AUTOSAR XML (schema 3.1.2)
package /Components/SWC_VSReg
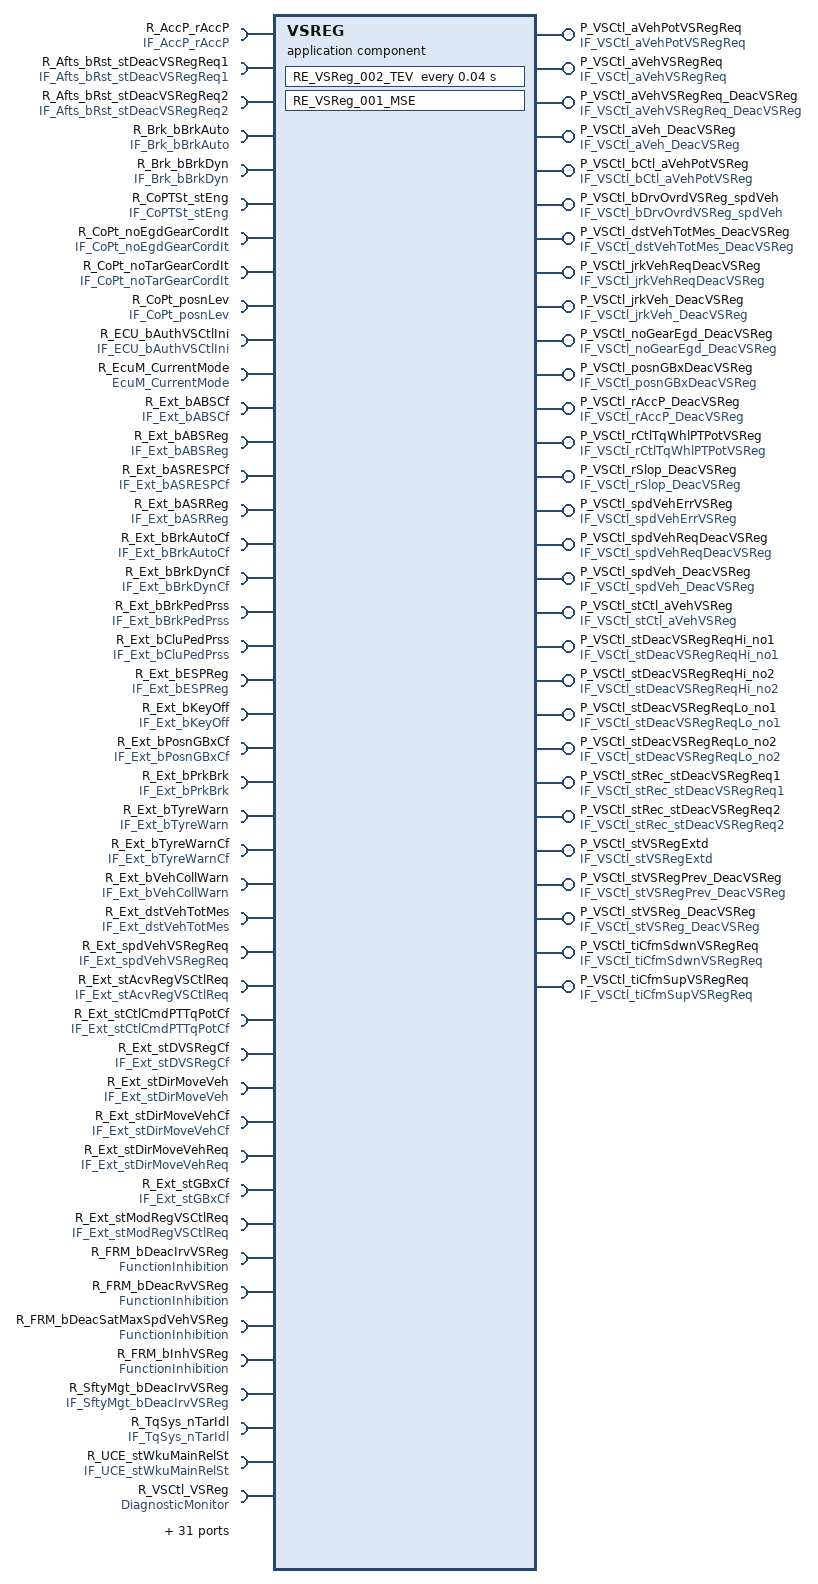
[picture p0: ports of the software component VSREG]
  application software component type VSREG  # VSReg
    29 x provide port:
      P_VSCtl_aVehPotVSRegReq: unqueued-sender-com-spec{data-element=VSCtl_aVehPotVSRegReq, can-invalidate=false, init-value=ConstantValue}, provided-interface=IF_VSCtl_aVehPotVSRegReq
      P_VSCtl_aVehVSRegReq: unqueued-sender-com-spec{data-element=VSCtl_aVehVSRegReq, can-invalidate=false, init-value=ConstantValue1}, provided-interface=IF_VSCtl_aVehVSRegReq
      P_VSCtl_aVehVSRegReq_DeacVSReg: unqueued-sender-com-spec{data-element=VSCtl_aVehVSRegReq_DeacVSReg, can-invalidate=false, init-value=C_SInt16_m10240}, provided-interface=IF_VSCtl_aVehVSRegReq_DeacVSReg
      P_VSCtl_aVeh_DeacVSReg: unqueued-sender-com-spec{data-element=VSCtl_aVeh_DeacVSReg, can-invalidate=false, init-value=C_SInt16_0}, provided-interface=IF_VSCtl_aVeh_DeacVSReg
      P_VSCtl_bCtl_aVehPotVSReg: unqueued-sender-com-spec{data-element=VSCtl_bCtl_aVehPotVSReg, can-invalidate=false, init-value=ConstantValue3}, provided-interface=IF_VSCtl_bCtl_aVehPotVSReg
      P_VSCtl_bDrvOvrdVSReg_spdVeh: unqueued-sender-com-spec{data-element=VSCtl_bDrvOvrdVSReg_spdVeh, can-invalidate=false, init-value=ConstantValue5}, provided-interface=IF_VSCtl_bDrvOvrdVSReg_spdVeh
      P_VSCtl_dstVehTotMes_DeacVSReg: unqueued-sender-com-spec{data-element=VSCtl_dstVehTotMes_DeacVSReg, can-invalidate=false, init-value=C_UInt32_0}, provided-interface=IF_VSCtl_dstVehTotMes_DeacVSReg
      P_VSCtl_jrkVehReqDeacVSReg: unqueued-sender-com-spec{data-element=VSCtl_jrkVehReqDeacVSReg, can-invalidate=false, init-value=C_SInt16_07}, provided-interface=IF_VSCtl_jrkVehReqDeacVSReg
      P_VSCtl_jrkVeh_DeacVSReg: unqueued-sender-com-spec{data-element=VSCtl_jrkVeh_DeacVSReg, can-invalidate=false, init-value=C_SInt16_09}, provided-interface=IF_VSCtl_jrkVeh_DeacVSReg
      P_VSCtl_noGearEgd_DeacVSReg: unqueued-sender-com-spec{data-element=VSCtl_noGearEgd_DeacVSReg, can-invalidate=false, init-value=C_SInt8_0}, provided-interface=IF_VSCtl_noGearEgd_DeacVSReg
      P_VSCtl_posnGBxDeacVSReg: unqueued-sender-com-spec{data-element=VSCtl_posnGBxDeacVSReg, can-invalidate=false, init-value=C_UInt8_0}, provided-interface=IF_VSCtl_posnGBxDeacVSReg
      P_VSCtl_rAccP_DeacVSReg: unqueued-sender-com-spec{data-element=VSCtl_rAccP_DeacVSReg, can-invalidate=false, init-value=C_UInt16_12800}, provided-interface=IF_VSCtl_rAccP_DeacVSReg
      P_VSCtl_rCtlTqWhlPTPotVSReg: unqueued-sender-com-spec{data-element=VSCtl_rCtlTqWhlPTPotVSReg, can-invalidate=false, init-value=ConstantValue11}, provided-interface=IF_VSCtl_rCtlTqWhlPTPotVSReg
      P_VSCtl_rSlop_DeacVSReg: unqueued-sender-com-spec{data-element=VSCtl_rSlop_DeacVSReg, can-invalidate=false, init-value=C_SInt16_013}, provided-interface=IF_VSCtl_rSlop_DeacVSReg
      P_VSCtl_spdVehErrVSReg: unqueued-sender-com-spec{data-element=VSCtl_spdVehErrVSReg, can-invalidate=false, init-value=C_SInt16_015}, provided-interface=IF_VSCtl_spdVehErrVSReg
      P_VSCtl_spdVehReqDeacVSReg: unqueued-sender-com-spec{data-element=VSCtl_spdVehReqDeacVSReg, can-invalidate=false, init-value=C_UInt8_017}, provided-interface=IF_VSCtl_spdVehReqDeacVSReg
      P_VSCtl_spdVeh_DeacVSReg: unqueued-sender-com-spec{data-element=VSCtl_spdVeh_DeacVSReg, can-invalidate=false, init-value=C_UInt16_0}, provided-interface=IF_VSCtl_spdVeh_DeacVSReg
      P_VSCtl_stCtl_aVehVSReg: unqueued-sender-com-spec{data-element=VSCtl_stCtl_aVehVSReg, can-invalidate=false, init-value=ConstantValue19}, provided-interface=IF_VSCtl_stCtl_aVehVSReg
      P_VSCtl_stDeacVSRegReqHi_no1: unqueued-sender-com-spec{data-element=VSCtl_stDeacVSRegReqHi_no1, can-invalidate=false, init-value=C_UInt32_2097151}, provided-interface=IF_VSCtl_stDeacVSRegReqHi_no1
      P_VSCtl_stDeacVSRegReqHi_no2: unqueued-sender-com-spec{data-element=VSCtl_stDeacVSRegReqHi_no2, can-invalidate=false, init-value=C_UInt32_209715121}, provided-interface=IF_VSCtl_stDeacVSRegReqHi_no2
      P_VSCtl_stDeacVSRegReqLo_no1: unqueued-sender-com-spec{data-element=VSCtl_stDeacVSRegReqLo_no1, can-invalidate=false, init-value=C_UInt32_67108863}, provided-interface=IF_VSCtl_stDeacVSRegReqLo_no1
      P_VSCtl_stDeacVSRegReqLo_no2: unqueued-sender-com-spec{data-element=VSCtl_stDeacVSRegReqLo_no2, can-invalidate=false, init-value=C_UInt32_6710886323}, provided-interface=IF_VSCtl_stDeacVSRegReqLo_no2
      P_VSCtl_stRec_stDeacVSRegReq1: unqueued-sender-com-spec{data-element=VSCtl_stRec_stDeacVSRegReq1, can-invalidate=false, init-value=C_UInt8_025}, provided-interface=IF_VSCtl_stRec_stDeacVSRegReq1
      P_VSCtl_stRec_stDeacVSRegReq2: unqueued-sender-com-spec{data-element=VSCtl_stRec_stDeacVSRegReq2, can-invalidate=false, init-value=C_UInt8_027}, provided-interface=IF_VSCtl_stRec_stDeacVSRegReq2
      P_VSCtl_stVSRegExtd: unqueued-sender-com-spec{data-element=VSCtl_stVSRegExtd, can-invalidate=false, init-value=ConstantValue29}, provided-interface=IF_VSCtl_stVSRegExtd
      P_VSCtl_stVSRegPrev_DeacVSReg: unqueued-sender-com-spec{data-element=VSCtl_stVSRegPrev_DeacVSReg, can-invalidate=false, init-value=C_UInt8_031}, provided-interface=IF_VSCtl_stVSRegPrev_DeacVSReg
      P_VSCtl_stVSReg_DeacVSReg: unqueued-sender-com-spec{data-element=VSCtl_stVSReg_DeacVSReg, can-invalidate=false, init-value=C_UInt8_033}, provided-interface=IF_VSCtl_stVSReg_DeacVSReg
      P_VSCtl_tiCfmSdwnVSRegReq: unqueued-sender-com-spec{data-element=VSCtl_tiCfmSdwnVSRegReq, can-invalidate=false, init-value=ConstantValue35}, provided-interface=IF_VSCtl_tiCfmSdwnVSRegReq
      P_VSCtl_tiCfmSupVSRegReq: unqueued-sender-com-spec{data-element=VSCtl_tiCfmSupVSRegReq, can-invalidate=false, init-value=ConstantValue37}, provided-interface=IF_VSCtl_tiCfmSupVSRegReq
    75 x require port:
      R_AccP_rAccP: unqueued-receiver-com-spec{data-element=AccP_rAccP, init-value=ConstantValue39, resync-time=0}, required-interface=IF_AccP_rAccP
      R_Afts_bRst_stDeacVSRegReq1: unqueued-receiver-com-spec{data-element=Afts_bRst_stDeacVSRegReq1, init-value=C_Boolean_False, resync-time=0}, required-interface=IF_Afts_bRst_stDeacVSRegReq1
      R_Afts_bRst_stDeacVSRegReq2: unqueued-receiver-com-spec{data-element=Afts_bRst_stDeacVSRegReq2, init-value=C_Boolean_False41, resync-time=0}, required-interface=IF_Afts_bRst_stDeacVSRegReq2
      R_Brk_bBrkAuto: unqueued-receiver-com-spec{data-element=Brk_bBrkAuto, init-value=ConstantValue43, resync-time=0}, required-interface=IF_Brk_bBrkAuto
      R_Brk_bBrkDyn: unqueued-receiver-com-spec{data-element=Brk_bBrkDyn, init-value=ConstantValue45, resync-time=0}, required-interface=IF_Brk_bBrkDyn
      R_CoPTSt_stEng: unqueued-receiver-com-spec{data-element=CoPTSt_stEng, init-value=ConstantValue47, resync-time=0}, required-interface=IF_CoPTSt_stEng
      R_CoPt_noEgdGearCordIt: unqueued-receiver-com-spec{data-element=CoPt_noEgdGearCordIt, init-value=ConstantValue49, resync-time=0}, required-interface=IF_CoPt_noEgdGearCordIt
      R_CoPt_noTarGearCordIt: unqueued-receiver-com-spec{data-element=CoPt_noTarGearCordIt, init-value=ConstantValue51, resync-time=0}, required-interface=IF_CoPt_noTarGearCordIt
      R_CoPt_posnLev: unqueued-receiver-com-spec{data-element=CoPt_posnLev, init-value=ConstantValue53, resync-time=0}, required-interface=IF_CoPt_posnLev
      R_ECU_bAuthVSCtlIni: unqueued-receiver-com-spec{data-element=ECU_bAuthVSCtlIni, init-value=ConstantValue55, resync-time=0}, required-interface=IF_ECU_bAuthVSCtlIni
      R_EcuM_CurrentMode: required-interface=EcuM_CurrentMode  # Requirement: 01552_09_00532-SSTG-C007(2)
      R_Ext_bABSCf: unqueued-receiver-com-spec{data-element=Ext_bABSCf, init-value=C_Boolean_False57, resync-time=0}, required-interface=IF_Ext_bABSCf
      R_Ext_bABSReg: unqueued-receiver-com-spec{data-element=Ext_bABSReg, init-value=C_Boolean_False59, resync-time=0}, required-interface=IF_Ext_bABSReg
      R_Ext_bASRESPCf: unqueued-receiver-com-spec{data-element=Ext_bASRESPCf, init-value=C_Boolean_False61, resync-time=0}, required-interface=IF_Ext_bASRESPCf
      R_Ext_bASRReg: unqueued-receiver-com-spec{data-element=Ext_bASRReg, init-value=C_Boolean_False63, resync-time=0}, required-interface=IF_Ext_bASRReg
      R_Ext_bBrkAutoCf: unqueued-receiver-com-spec{data-element=Ext_bBrkAutoCf, init-value=ConstantValue65, resync-time=0}, required-interface=IF_Ext_bBrkAutoCf
      R_Ext_bBrkDynCf: unqueued-receiver-com-spec{data-element=Ext_bBrkDynCf, init-value=ConstantValue67, resync-time=0}, required-interface=IF_Ext_bBrkDynCf
      R_Ext_bBrkPedPrss: unqueued-receiver-com-spec{data-element=Ext_bBrkPedPrss, init-value=ConstantValue69, resync-time=0}, required-interface=IF_Ext_bBrkPedPrss
      R_Ext_bCluPedPrss: unqueued-receiver-com-spec{data-element=Ext_bCluPedPrss, init-value=ConstantValue71, resync-time=0}, required-interface=IF_Ext_bCluPedPrss
      R_Ext_bESPReg: unqueued-receiver-com-spec{data-element=Ext_bESPReg, init-value=C_Boolean_False73, resync-time=0}, required-interface=IF_Ext_bESPReg
      R_Ext_bKeyOff: unqueued-receiver-com-spec{data-element=Ext_bKeyOff, init-value=ConstantValue75, resync-time=0}, required-interface=IF_Ext_bKeyOff
      R_Ext_bPosnGBxCf: unqueued-receiver-com-spec{data-element=Ext_bPosnGBxCf, init-value=ConstantValue77, resync-time=0}, required-interface=IF_Ext_bPosnGBxCf
      R_Ext_bPrkBrk: unqueued-receiver-com-spec{data-element=Ext_bPrkBrk, init-value=ConstantValue79, resync-time=0}, required-interface=IF_Ext_bPrkBrk
      R_Ext_bTyreWarn: unqueued-receiver-com-spec{data-element=Ext_bTyreWarn, init-value=ConstantValue81, resync-time=0}, required-interface=IF_Ext_bTyreWarn
      R_Ext_bTyreWarnCf: unqueued-receiver-com-spec{data-element=Ext_bTyreWarnCf, init-value=ConstantValue83, resync-time=0}, required-interface=IF_Ext_bTyreWarnCf
      R_Ext_bVehCollWarn: unqueued-receiver-com-spec{data-element=Ext_bVehCollWarn, init-value=C_Boolean_False85, resync-time=0}, required-interface=IF_Ext_bVehCollWarn
      R_Ext_dstVehTotMes: unqueued-receiver-com-spec{data-element=Ext_dstVehTotMes, init-value=ConstantValue87, resync-time=0}, required-interface=IF_Ext_dstVehTotMes
      R_Ext_spdVehVSRegReq: unqueued-receiver-com-spec{data-element=Ext_spdVehVSRegReq, init-value=C_UInt8_089, resync-time=0}, required-interface=IF_Ext_spdVehVSRegReq
      R_Ext_stAcvRegVSCtlReq: unqueued-receiver-com-spec{data-element=Ext_stAcvRegVSCtlReq, init-value=ConstantValue91, resync-time=0}, required-interface=IF_Ext_stAcvRegVSCtlReq
      R_Ext_stCtlCmdPTTqPotCf: unqueued-receiver-com-spec{data-element=Ext_stCtlCmdPTTqPotCf, init-value=ConstantValue93, resync-time=0}, required-interface=IF_Ext_stCtlCmdPTTqPotCf
      R_Ext_stDVSRegCf: unqueued-receiver-com-spec{data-element=Ext_stDVSRegCf, init-value=ConstantValue95, resync-time=0}, required-interface=IF_Ext_stDVSRegCf
      R_Ext_stDirMoveVeh: unqueued-receiver-com-spec{data-element=Ext_stDirMoveVeh, init-value=C_UInt8_097, resync-time=0}, required-interface=IF_Ext_stDirMoveVeh
      R_Ext_stDirMoveVehCf: unqueued-receiver-com-spec{data-element=Ext_stDirMoveVehCf, init-value=C_Boolean_False99, resync-time=0}, required-interface=IF_Ext_stDirMoveVehCf
      R_Ext_stDirMoveVehReq: unqueued-receiver-com-spec{data-element=Ext_stDirMoveVehReq, init-value=C_UInt8_0101, resync-time=0}, required-interface=IF_Ext_stDirMoveVehReq
      R_Ext_stGBxCf: unqueued-receiver-com-spec{data-element=Ext_stGBxCf, init-value=ConstantValue103, resync-time=0}, required-interface=IF_Ext_stGBxCf
      R_Ext_stModRegVSCtlReq: unqueued-receiver-com-spec{data-element=Ext_stModRegVSCtlReq, init-value=ConstantValue105, resync-time=0}, required-interface=IF_Ext_stModRegVSCtlReq
      R_FRM_bDeacIrvVSReg: required-interface=FunctionInhibition
      R_FRM_bDeacRvVSReg: required-interface=FunctionInhibition
      R_FRM_bDeacSatMaxSpdVehVSReg: required-interface=FunctionInhibition
      R_FRM_bInhVSReg: required-interface=FunctionInhibition
      R_SftyMgt_bDeacIrvVSReg: unqueued-receiver-com-spec{data-element=SftyMgt_bDeacIrvVSReg, init-value=C_Boolean_False107, resync-time=0}, required-interface=IF_SftyMgt_bDeacIrvVSReg
      R_TqSys_nTarIdl: unqueued-receiver-com-spec{data-element=TqSys_nTarIdl, init-value=ConstantValue109, resync-time=0}, required-interface=IF_TqSys_nTarIdl
      R_UCE_stWkuMainRelSt: required-interface=IF_UCE_stWkuMainRelSt  # Requirement: 01552_09_00532-SSTG-C011(1)
      R_VSCtl_VSReg: required-interface=DiagnosticMonitor
      R_VSCtl_VSRegBody: required-interface=DiagnosticMonitor
      R_VSCtl_VSRegVeh: required-interface=DiagnosticMonitor
      R_VSCtl_aVeh: unqueued-receiver-com-spec{data-element=VSCtl_aVeh, init-value=ConstantValue111, resync-time=0}, required-interface=IF_VSCtl_aVeh
      R_VSCtl_aVehPTIni: unqueued-receiver-com-spec{data-element=VSCtl_aVehPTIni, init-value=ConstantValue113, resync-time=0}, required-interface=IF_VSCtl_aVehPTIni
      R_VSCtl_aVehPTMax: unqueued-receiver-com-spec{data-element=VSCtl_aVehPTMax, init-value=ConstantValue115, resync-time=0}, required-interface=IF_VSCtl_aVehPTMax
      R_VSCtl_aVehPTMin: unqueued-receiver-com-spec{data-element=VSCtl_aVehPTMin, init-value=ConstantValue117, resync-time=0}, required-interface=IF_VSCtl_aVehPTMin
      R_VSCtl_aVehPreCoVSCtlReq: unqueued-receiver-com-spec{data-element=VSCtl_aVehPreCoVSCtlReq, init-value=ConstantValue119, resync-time=0}, required-interface=IF_VSCtl_aVehPreCoVSCtlReq
      R_VSCtl_aVehReq: unqueued-receiver-com-spec{data-element=VSCtl_aVehReq, init-value=ConstantValue121, resync-time=0}, required-interface=IF_VSCtl_aVehReq
      R_VSCtl_bAvlTqWhlPT_no1: unqueued-receiver-com-spec{data-element=VSCtl_bAvlTqWhlPT_no1, init-value=ConstantValue123, resync-time=0}, required-interface=IF_VSCtl_bAvlTqWhlPT_no1
      R_VSCtl_bAvlTqWhlPT_no2: unqueued-receiver-com-spec{data-element=VSCtl_bAvlTqWhlPT_no2, init-value=ConstantValue125, resync-time=0}, required-interface=IF_VSCtl_bAvlTqWhlPT_no2
      R_VSCtl_bAvlTqWhlPT_no3: unqueued-receiver-com-spec{data-element=VSCtl_bAvlTqWhlPT_no3, init-value=ConstantValue127, resync-time=0}, required-interface=IF_VSCtl_bAvlTqWhlPT_no3
      R_VSCtl_bCtlaTqPT: unqueued-receiver-com-spec{data-element=VSCtl_bCtlaTqPT, init-value=ConstantValue129, resync-time=0}, required-interface=IF_VSCtl_bCtlaTqPT
      R_VSCtl_bDrvOvrdVSReg_aVeh: unqueued-receiver-com-spec{data-element=VSCtl_bDrvOvrdVSReg_aVeh, init-value=ConstantValue131, resync-time=0}, required-interface=IF_VSCtl_bDrvOvrdVSReg_aVeh
      R_VSCtl_bEndTranVSReg: unqueued-receiver-com-spec{data-element=VSCtl_bEndTranVSReg, init-value=ConstantValue133, resync-time=0}, required-interface=IF_VSCtl_bEndTranVSReg
      R_VSCtl_bNbGearEgdChg: unqueued-receiver-com-spec{data-element=VSCtl_bNbGearEgdChg, init-value=ConstantValue135, resync-time=0}, required-interface=IF_VSCtl_bNbGearEgdChg
      R_VSCtl_grdRatConvTra: unqueued-receiver-com-spec{data-element=VSCtl_grdRatConvTra, init-value=ConstantValue137, resync-time=0}, required-interface=IF_VSCtl_grdRatConvTra
      R_VSCtl_jrkVeh: unqueued-receiver-com-spec{data-element=VSCtl_jrkVeh, init-value=ConstantValue139, resync-time=0}, required-interface=IF_VSCtl_jrkVeh
      R_VSCtl_nEngFil: unqueued-receiver-com-spec{data-element=VSCtl_nEngFil, init-value=ConstantValue141, resync-time=0}, required-interface=IF_VSCtl_nEngFil
      R_VSCtl_rConvTra: unqueued-receiver-com-spec{data-element=VSCtl_rConvTra, init-value=ConstantValue143, resync-time=0}, required-interface=IF_VSCtl_rConvTra
      R_VSCtl_rSlop: unqueued-receiver-com-spec{data-element=VSCtl_rSlop, init-value=ConstantValue145, resync-time=0}, required-interface=IF_VSCtl_rSlop
      R_VSCtl_rTqWhlPTDrvReq: unqueued-receiver-com-spec{data-element=VSCtl_rTqWhlPTDrvReq, init-value=ConstantValue147, resync-time=0}, required-interface=IF_VSCtl_rTqWhlPTDrvReq
      R_VSCtl_rWhlSlip_no1: unqueued-receiver-com-spec{data-element=VSCtl_rWhlSlip_no1, init-value=ConstantValue149, resync-time=0}, required-interface=IF_VSCtl_rWhlSlip_no1
      R_VSCtl_rWhlSlip_no2: unqueued-receiver-com-spec{data-element=VSCtl_rWhlSlip_no2, init-value=ConstantValue151, resync-time=0}, required-interface=IF_VSCtl_rWhlSlip_no2
      R_VSCtl_spdVeh: unqueued-receiver-com-spec{data-element=VSCtl_spdVeh, init-value=ConstantValue153, resync-time=0}, required-interface=IF_VSCtl_spdVeh
      R_VSCtl_stCtl_noGear: unqueued-receiver-com-spec{data-element=VSCtl_stCtl_noGear, init-value=ConstantValue155, resync-time=0}, required-interface=IF_VSCtl_stCtl_noGear
      R_VSCtl_stDeacVSCtlInfo: unqueued-receiver-com-spec{data-element=VSCtl_stDeacVSCtlInfo, init-value=ConstantValue157, resync-time=0}, required-interface=IF_VSCtl_stDeacVSCtlInfo
      R_VSCtl_stVSCtlInfo: unqueued-receiver-com-spec{data-element=VSCtl_stVSCtlInfo, init-value=ConstantValue159, resync-time=0}, required-interface=IF_VSCtl_stVSCtlInfo
      R_VSReg_GetTimer_1ms_U32: required-interface=IF_CS_FRunTime_1MS_U32
      R_VehEst_bORng_nPT: unqueued-receiver-com-spec{data-element=VehEst_bORng_nPT, init-value=C_Boolean_False161, resync-time=0}, required-interface=IF_VehEst_bORng_nPT
      R_Veh_spdVeh: unqueued-receiver-com-spec{data-element=Veh_spdVeh, init-value=ConstantValue163, resync-time=0}, required-interface=IF_Veh_spdVeh
      R_Ext_bCtlCmdPTTqCf: unqueued-receiver-com-spec{data-element=Ext_bCtlCmdPTTqCf, init-value=ConstantValue165, resync-time=0}, required-interface=IF_Ext_bCtlCmdPTTqCf  # R_Ext_bVSMaxpCf
  94 x constant specification:
    C_Boolean_False
      value:
        boolean literal C_Boolean_False: type=DT_Afts_bRst_stDeacVSRegReq1, value=false
    C_Boolean_False107
      value:
        boolean literal C_Boolean_False107: type=DT_SftyMgt_bDeacIrvVSReg, value=false
    C_Boolean_False161
      value:
        boolean literal C_Boolean_False161: type=DT_VehEst_bORng_nPT, value=false
    C_Boolean_False41
      value:
        boolean literal C_Boolean_False41: type=DT_Afts_bRst_stDeacVSRegReq2, value=false
    C_Boolean_False57
      value:
        boolean literal C_Boolean_False57: type=DT_Ext_bABSCf, value=false
    C_Boolean_False59
      value:
        boolean literal C_Boolean_False59: type=DT_Ext_bABSReg, value=false
    C_Boolean_False61
      value:
        boolean literal C_Boolean_False61: type=DT_Ext_bASRESPCf, value=false
    C_Boolean_False63
      value:
        boolean literal C_Boolean_False63: type=DT_Ext_bASRReg, value=false
    C_Boolean_False73
      value:
        boolean literal C_Boolean_False73: type=DT_Ext_bESPReg, value=false
    C_Boolean_False85
      value:
        boolean literal C_Boolean_False85: type=DT_Ext_bVehCollWarn, value=false
    C_Boolean_False99
      value:
        boolean literal C_Boolean_False99: type=DT_Ext_stDirMoveVehCf, value=false
    C_SInt16_0
      value:
        integer literal C_SInt16_0: type=DT_VSCtl_aVeh_DeacVSReg, value=0
    C_SInt16_013
      value:
        integer literal C_SInt16_013: type=DT_VSCtl_rSlop_DeacVSReg, value=0
    C_SInt16_015
      value:
        integer literal C_SInt16_015: type=DT_VSCtl_spdVehErrVSReg, value=0
    C_SInt16_07
      value:
        integer literal C_SInt16_07: type=DT_VSCtl_jrkVehReqDeacVSReg, value=0
    C_SInt16_09
      value:
        integer literal C_SInt16_09: type=DT_VSCtl_jrkVeh_DeacVSReg, value=0
    C_SInt16_m10240
      value:
        integer literal C_SInt16_m10240: type=DT_VSCtl_aVehVSRegReq_DeacVSReg, value=-10240
    C_SInt8_0
      value:
        integer literal C_SInt8_0: type=DT_VSCtl_noGearEgd_DeacVSReg, value=0
    C_UInt16_0
      value:
        integer literal C_UInt16_0: type=DT_VSCtl_spdVeh_DeacVSReg, value=0
    C_UInt16_12800
      value:
        integer literal C_UInt16_12800: type=DT_VSCtl_rAccP_DeacVSReg, value=12800
    C_UInt32_0
      value:
        integer literal C_UInt32_0: type=DT_VSCtl_dstVehTotMes_DeacVSReg, value=0
    C_UInt32_2097151
      value:
        integer literal C_UInt32_2097151: type=DT_VSCtl_stDeacVSRegReqHi_no1, value=2097151
    C_UInt32_209715121
      value:
        integer literal C_UInt32_209715121: type=DT_VSCtl_stDeacVSRegReqHi_no2, value=2097151
    C_UInt32_67108863
      value:
        integer literal C_UInt32_67108863: type=DT_VSCtl_stDeacVSRegReqLo_no1, value=67108863
    C_UInt32_6710886323
      value:
        integer literal C_UInt32_6710886323: type=DT_VSCtl_stDeacVSRegReqLo_no2, value=67108863
    C_UInt8_0
      value:
        integer literal C_UInt8_0: type=DT_VSCtl_posnGBxDeacVSReg, value=0
    C_UInt8_0101
      value:
        integer literal C_UInt8_0101: type=DT_Ext_stDirMoveVehReq, value=0
    C_UInt8_017
      value:
        integer literal C_UInt8_017: type=DT_VSCtl_spdVehReqDeacVSReg, value=0
    C_UInt8_025
      value:
        integer literal C_UInt8_025: type=DT_VSCtl_stRec_stDeacVSRegReq1, value=0
    C_UInt8_027
      value:
        integer literal C_UInt8_027: type=DT_VSCtl_stRec_stDeacVSRegReq2, value=0
    C_UInt8_031
      value:
        integer literal C_UInt8_031: type=DT_VSCtl_stVSRegPrev_DeacVSReg, value=0
    C_UInt8_033
      value:
        integer literal C_UInt8_033: type=DT_VSCtl_stVSReg_DeacVSReg, value=0
    C_UInt8_089
      value:
        integer literal C_UInt8_089: type=DT_Ext_spdVehVSRegReq, value=0
    C_UInt8_097
      value:
        integer literal C_UInt8_097: type=DT_Ext_stDirMoveVeh, value=0
    ConstantValue
      value:
        integer literal ConstantValue: type=DT_VSCtl_aVehPotVSRegReq, value=0
    ConstantValue1
      value:
        integer literal ConstantValue1: type=DT_VSCtl_aVehVSRegReq, value=0
    ConstantValue103
      value:
        integer literal ConstantValue103: type=DT_Ext_stGBxCf, value=0
    ConstantValue105
      value:
        integer literal ConstantValue105: type=DT_Ext_stModRegVSCtlReq, value=0
    ConstantValue109
      value:
        integer literal ConstantValue109: type=DT_TqSys_nTarIdl, value=0
    ConstantValue11
      value:
        integer literal ConstantValue11: type=DT_VSCtl_rCtlTqWhlPTPotVSReg, value=0
    ConstantValue111
      value:
        integer literal ConstantValue111: type=DT_VSCtl_aVeh, value=0
    ConstantValue113
      value:
        integer literal ConstantValue113: type=DT_VSCtl_aVehPTIni, value=0
    ConstantValue115
      value:
        integer literal ConstantValue115: type=DT_VSCtl_aVehPTMax, value=0
    ConstantValue117
      value:
        integer literal ConstantValue117: type=DT_VSCtl_aVehPTMin, value=0
    ConstantValue119
      value:
        integer literal ConstantValue119: type=DT_VSCtl_aVehPreCoVSCtlReq, value=0
    ConstantValue121
      value:
        integer literal ConstantValue121: type=DT_VSCtl_aVehReq, value=-10240
    ConstantValue123
      value:
        boolean literal ConstantValue123: type=DT_VSCtl_bAvlTqWhlPT_no1, value=false
    ConstantValue125
      value:
        boolean literal ConstantValue125: type=DT_VSCtl_bAvlTqWhlPT_no2, value=false
    ConstantValue127
      value:
        boolean literal ConstantValue127: type=DT_VSCtl_bAvlTqWhlPT_no3, value=false
    ConstantValue129
      value:
        boolean literal ConstantValue129: type=DT_VSCtl_bCtlaTqPT, value=false
    ConstantValue131
      value:
        boolean literal ConstantValue131: type=DT_VSCtl_bDrvOvrdVSReg_aVeh, value=false
    ConstantValue133
      value:
        boolean literal ConstantValue133: type=DT_VSCtl_bEndTranVSReg, value=true
    ConstantValue135
      value:
        boolean literal ConstantValue135: type=DT_VSCtl_bNbGearEgdChg, value=false
    ConstantValue137
      value:
        integer literal ConstantValue137: type=DT_VSCtl_grdRatConvTra, value=0
    ConstantValue139
      value:
        integer literal ConstantValue139: type=DT_VSCtl_jrkVeh, value=0
    ConstantValue141
      value:
        integer literal ConstantValue141: type=DT_VSCtl_nEngFil, value=0
    ConstantValue143
      value:
        integer literal ConstantValue143: type=DT_VSCtl_rConvTra, value=2560
    ConstantValue145
      value:
        integer literal ConstantValue145: type=DT_VSCtl_rSlop, value=0
    ConstantValue147
      value:
        integer literal ConstantValue147: type=DT_VSCtl_rTqWhlPTDrvReq, value=0
    ConstantValue149
      value:
        integer literal ConstantValue149: type=DT_VSCtl_rWhlSlip_no1, value=0
    ConstantValue151
      value:
        integer literal ConstantValue151: type=DT_VSCtl_rWhlSlip_no2, value=0
    ConstantValue153
      value:
        integer literal ConstantValue153: type=DT_VSCtl_spdVeh, value=0
    ConstantValue155
      value:
        integer literal ConstantValue155: type=DT_VSCtl_stCtl_noGear, value=0
    ConstantValue157
      value:
        integer literal ConstantValue157: type=DT_VSCtl_stDeacVSCtlInfo, value=32
    ConstantValue159
      value:
        integer literal ConstantValue159: type=DT_VSCtl_stVSCtlInfo, value=0
    ConstantValue163
      value:
        integer literal ConstantValue163: type=DT_Veh_spdVeh, value=0
    ConstantValue165
      value:
        boolean literal ConstantValue165: type=DT_Ext_bCtlCmdPTTqCf, value=false
    ConstantValue19
      value:
        integer literal ConstantValue19: type=DT_VSCtl_stCtl_aVehVSReg, value=0
    ConstantValue29
      value:
        integer literal ConstantValue29: type=DT_VSCtl_stVSRegExtd, value=0
    ConstantValue3
      value:
        integer literal ConstantValue3: type=DT_VSCtl_bCtl_aVehPotVSReg, value=0
    ConstantValue35
      value:
        integer literal ConstantValue35: type=DT_VSCtl_tiCfmSdwnVSRegReq, value=0
    ConstantValue37
      value:
        integer literal ConstantValue37: type=DT_VSCtl_tiCfmSupVSRegReq, value=0
    ConstantValue39
      value:
        integer literal ConstantValue39: type=DT_AccP_rAccP, value=0
    ConstantValue43
      value:
        boolean literal ConstantValue43: type=DT_Brk_bBrkAuto, value=false
    ConstantValue45
      value:
        boolean literal ConstantValue45: type=DT_Brk_bBrkDyn, value=false
    ConstantValue47
      value:
        integer literal ConstantValue47: type=DT_CoPTSt_stEng, value=1
    ConstantValue49
      value:
        integer literal ConstantValue49: type=DT_CoPt_noEgdGearCordIt, value=0
    ConstantValue5
      value:
        boolean literal ConstantValue5: type=DT_VSCtl_bDrvOvrdVSReg_spdVeh, value=false
    ConstantValue51
      value:
        integer literal ConstantValue51: type=DT_CoPt_noTarGearCordIt, value=0
    ConstantValue53
      value:
        integer literal ConstantValue53: type=DT_CoPt_posnLev, value=0
    ConstantValue55
      value:
        boolean literal ConstantValue55: type=DT_ECU_bAuthVSCtlIni, value=false
    ConstantValue65
      value:
        boolean literal ConstantValue65: type=DT_Ext_bBrkAutoCf, value=false
    ConstantValue67
      value:
        boolean literal ConstantValue67: type=DT_Ext_bBrkDynCf, value=false
    ConstantValue69
      value:
        boolean literal ConstantValue69: type=DT_Ext_bBrkPedPrss, value=false
    ConstantValue71
      value:
        boolean literal ConstantValue71: type=DT_Ext_bCluPedPrss, value=false
    ConstantValue75
      value:
        boolean literal ConstantValue75: type=DT_Ext_bKeyOff, value=false
    ConstantValue77
      value:
        boolean literal ConstantValue77: type=DT_Ext_bPosnGBxCf, value=false
    ConstantValue79
      value:
        boolean literal ConstantValue79: type=DT_Ext_bPrkBrk, value=false
    ConstantValue81
      value:
        boolean literal ConstantValue81: type=DT_Ext_bTyreWarn, value=false
    ConstantValue83
      value:
        boolean literal ConstantValue83: type=DT_Ext_bTyreWarnCf, value=false
    ConstantValue87
      value:
        integer literal ConstantValue87: type=DT_Ext_dstVehTotMes, value=0
    ConstantValue91
      value:
        integer literal ConstantValue91: type=DT_Ext_stAcvRegVSCtlReq, value=0
    ConstantValue93
      value:
        integer literal ConstantValue93: type=DT_Ext_stCtlCmdPTTqPotCf, value=0
    ConstantValue95
      value:
        integer literal ConstantValue95: type=DT_Ext_stDVSRegCf, value=0
  internal behavior IB_VSReg: component=VSREG
    mode switch event EV_VSReg_001_MSE: start-on-event=RE_VSReg_001_MSE, activation=ENTRY, mode=R_EcuM_CurrentMode.currentMode.RUN
    timing event EV_VSReg_002_TEV: mode-dependency=dependent-on-mode=[R_UCE_stWkuMainRelSt.RCD_stWkuMainRelSt.Invalid, R_UCE_stWkuMainRelSt.RCD_stWkuMainRelSt.PostMainWakeUp, R_UCE_stWkuMainRelSt.RCD_stWkuMainRelSt.PreMainWakeUp], start-on-event=RE_VSReg_002_TEV, period=0.04
    runnable RE_VSReg_001_MSE  # RE_01552_10_02846_10ms_init
      29 x data send point:
        ds_VSCtl_tiCfmSdwnVSRegReq: data-element=P_VSCtl_tiCfmSdwnVSRegReq.VSCtl_tiCfmSdwnVSRegReq
        ds_VSCtl_bCtl_aVehPotVSReg: data-element=P_VSCtl_bCtl_aVehPotVSReg.VSCtl_bCtl_aVehPotVSReg
        ds_VSCtl_stVSReg_DeacVSReg: data-element=P_VSCtl_stVSReg_DeacVSReg.VSCtl_stVSReg_DeacVSReg
        ds_VSCtl_spdVehReqDeacVSReg: data-element=P_VSCtl_spdVehReqDeacVSReg.VSCtl_spdVehReqDeacVSReg
        ds_VSCtl_aVeh_DeacVSReg: data-element=P_VSCtl_aVeh_DeacVSReg.VSCtl_aVeh_DeacVSReg
        ds_VSCtl_jrkVeh_DeacVSReg: data-element=P_VSCtl_jrkVeh_DeacVSReg.VSCtl_jrkVeh_DeacVSReg
        ds_VSCtl_stDeacVSRegReqHi_no1: data-element=P_VSCtl_stDeacVSRegReqHi_no1.VSCtl_stDeacVSRegReqHi_no1
        ds_VSCtl_dstVehTotMes_DeacVSReg: data-element=P_VSCtl_dstVehTotMes_DeacVSReg.VSCtl_dstVehTotMes_DeacVSReg
        ds_VSCtl_stCtl_aVehVSReg: data-element=P_VSCtl_stCtl_aVehVSReg.VSCtl_stCtl_aVehVSReg
        ds_VSCtl_spdVehErrVSReg: data-element=P_VSCtl_spdVehErrVSReg.VSCtl_spdVehErrVSReg
        ds_VSCtl_aVehVSRegReq: data-element=P_VSCtl_aVehVSRegReq.VSCtl_aVehVSRegReq
        ds_VSCtl_bDrvOvrdVSReg_spdVeh: data-element=P_VSCtl_bDrvOvrdVSReg_spdVeh.VSCtl_bDrvOvrdVSReg_spdVeh
        ds_VSCtl_stDeacVSRegReqLo_no1: data-element=P_VSCtl_stDeacVSRegReqLo_no1.VSCtl_stDeacVSRegReqLo_no1
        ds_VSCtl_tiCfmSupVSRegReq: data-element=P_VSCtl_tiCfmSupVSRegReq.VSCtl_tiCfmSupVSRegReq
        ds_VSCtl_stVSRegPrev_DeacVSReg: data-element=P_VSCtl_stVSRegPrev_DeacVSReg.VSCtl_stVSRegPrev_DeacVSReg
        ds_VSCtl_posnGBxDeacVSReg: data-element=P_VSCtl_posnGBxDeacVSReg.VSCtl_posnGBxDeacVSReg
        ds_VSCtl_stDeacVSRegReqLo_no2: data-element=P_VSCtl_stDeacVSRegReqLo_no2.VSCtl_stDeacVSRegReqLo_no2
        ds_VSCtl_rSlop_DeacVSReg: data-element=P_VSCtl_rSlop_DeacVSReg.VSCtl_rSlop_DeacVSReg
        ds_VSCtl_stRec_stDeacVSRegReq1: data-element=P_VSCtl_stRec_stDeacVSRegReq1.VSCtl_stRec_stDeacVSRegReq1
        ds_VSCtl_stRec_stDeacVSRegReq2: data-element=P_VSCtl_stRec_stDeacVSRegReq2.VSCtl_stRec_stDeacVSRegReq2
        ds_VSCtl_aVehVSRegReq_DeacVSReg: data-element=P_VSCtl_aVehVSRegReq_DeacVSReg.VSCtl_aVehVSRegReq_DeacVSReg
        ds_VSCtl_aVehPotVSRegReq: data-element=P_VSCtl_aVehPotVSRegReq.VSCtl_aVehPotVSRegReq
        ds_VSCtl_stVSRegExtd: data-element=P_VSCtl_stVSRegExtd.VSCtl_stVSRegExtd
        ds_VSCtl_rAccP_DeacVSReg: data-element=P_VSCtl_rAccP_DeacVSReg.VSCtl_rAccP_DeacVSReg
        ds_VSCtl_stDeacVSRegReqHi_no2: data-element=P_VSCtl_stDeacVSRegReqHi_no2.VSCtl_stDeacVSRegReqHi_no2
        ds_VSCtl_jrkVehReqDeacVSReg: data-element=P_VSCtl_jrkVehReqDeacVSReg.VSCtl_jrkVehReqDeacVSReg
        ds_VSCtl_spdVeh_DeacVSReg: data-element=P_VSCtl_spdVeh_DeacVSReg.VSCtl_spdVeh_DeacVSReg
        ds_VSCtl_noGearEgd_DeacVSReg: data-element=P_VSCtl_noGearEgd_DeacVSReg.VSCtl_noGearEgd_DeacVSReg
        ds_VSCtl_rCtlTqWhlPTPotVSReg: data-element=P_VSCtl_rCtlTqWhlPTPotVSReg.VSCtl_rCtlTqWhlPTPotVSReg
      sync call ssp_GetTimer_1ms_U32: operation=R_VSReg_GetTimer_1ms_U32.GetTimer_1ms_U32
    runnable RE_VSReg_002_TEV  # RE_01552_10_02846_40ms
      65 x data receive point:
        dr_VSCtl_nEngFil: data-element=R_VSCtl_nEngFil.VSCtl_nEngFil
        dr_Ext_bABSCf: data-element=R_Ext_bABSCf.Ext_bABSCf
        dr_VehEst_bORng_nPT: data-element=R_VehEst_bORng_nPT.VehEst_bORng_nPT
        dr_Ext_bABSReg: data-element=R_Ext_bABSReg.Ext_bABSReg
        dr_Ext_bTyreWarnCf: data-element=R_Ext_bTyreWarnCf.Ext_bTyreWarnCf
        dr_Ext_bKeyOff: data-element=R_Ext_bKeyOff.Ext_bKeyOff
        dr_VSCtl_spdVeh: data-element=R_VSCtl_spdVeh.VSCtl_spdVeh
        dr_Brk_bBrkDyn: data-element=R_Brk_bBrkDyn.Brk_bBrkDyn
        dr_VSCtl_aVehPTMax: data-element=R_VSCtl_aVehPTMax.VSCtl_aVehPTMax
        dr_CoPt_noTarGearCordIt: data-element=R_CoPt_noTarGearCordIt.CoPt_noTarGearCordIt
        dr_ECU_bAuthVSCtlIni: data-element=R_ECU_bAuthVSCtlIni.ECU_bAuthVSCtlIni
        dr_Afts_bRst_stDeacVSRegReq1: data-element=R_Afts_bRst_stDeacVSRegReq1.Afts_bRst_stDeacVSRegReq1
        dr_Ext_stDirMoveVehCf: data-element=R_Ext_stDirMoveVehCf.Ext_stDirMoveVehCf
        dr_Ext_stCtlCmdPTTqPotCf: data-element=R_Ext_stCtlCmdPTTqPotCf.Ext_stCtlCmdPTTqPotCf
        dr_VSCtl_bAvlTqWhlPT_no2: data-element=R_VSCtl_bAvlTqWhlPT_no2.VSCtl_bAvlTqWhlPT_no2
        dr_CoPt_posnLev: data-element=R_CoPt_posnLev.CoPt_posnLev
        dr_VSCtl_rWhlSlip_no1: data-element=R_VSCtl_rWhlSlip_no1.VSCtl_rWhlSlip_no1
        dr_Afts_bRst_stDeacVSRegReq2: data-element=R_Afts_bRst_stDeacVSRegReq2.Afts_bRst_stDeacVSRegReq2
        dr_Ext_dstVehTotMes: data-element=R_Ext_dstVehTotMes.Ext_dstVehTotMes
        dr_Ext_bBrkPedPrss: data-element=R_Ext_bBrkPedPrss.Ext_bBrkPedPrss
        dr_Ext_bBrkDynCf: data-element=R_Ext_bBrkDynCf.Ext_bBrkDynCf
        dr_VSCtl_stCtl_noGear: data-element=R_VSCtl_stCtl_noGear.VSCtl_stCtl_noGear
        dr_VSCtl_bNbGearEgdChg: data-element=R_VSCtl_bNbGearEgdChg.VSCtl_bNbGearEgdChg
        dr_VSCtl_jrkVeh: data-element=R_VSCtl_jrkVeh.VSCtl_jrkVeh
        dr_Ext_stGBxCf: data-element=R_Ext_stGBxCf.Ext_stGBxCf
        dr_Ext_bVehCollWarn: data-element=R_Ext_bVehCollWarn.Ext_bVehCollWarn
        dr_Ext_bPrkBrk: data-element=R_Ext_bPrkBrk.Ext_bPrkBrk
        dr_Ext_bPosnGBxCf: data-element=R_Ext_bPosnGBxCf.Ext_bPosnGBxCf
        dr_Ext_bASRESPCf: data-element=R_Ext_bASRESPCf.Ext_bASRESPCf
        dr_VSCtl_aVeh: data-element=R_VSCtl_aVeh.VSCtl_aVeh
        dr_VSCtl_aVehPreCoVSCtlReq: data-element=R_VSCtl_aVehPreCoVSCtlReq.VSCtl_aVehPreCoVSCtlReq
        dr_Ext_bESPReg: data-element=R_Ext_bESPReg.Ext_bESPReg
        dr_CoPt_noEgdGearCordIt: data-element=R_CoPt_noEgdGearCordIt.CoPt_noEgdGearCordIt
        dr_VSCtl_stVSCtlInfo: data-element=R_VSCtl_stVSCtlInfo.VSCtl_stVSCtlInfo
        dr_VSCtl_bAvlTqWhlPT_no3: data-element=R_VSCtl_bAvlTqWhlPT_no3.VSCtl_bAvlTqWhlPT_no3
        dr_VSCtl_rSlop: data-element=R_VSCtl_rSlop.VSCtl_rSlop
        dr_VSCtl_rWhlSlip_no2: data-element=R_VSCtl_rWhlSlip_no2.VSCtl_rWhlSlip_no2
        dr_VSCtl_rConvTra: data-element=R_VSCtl_rConvTra.VSCtl_rConvTra
        dr_VSCtl_aVehReq: data-element=R_VSCtl_aVehReq.VSCtl_aVehReq
        dr_VSCtl_bCtlaTqPT: data-element=R_VSCtl_bCtlaTqPT.VSCtl_bCtlaTqPT
        dr_VSCtl_aVehPTIni: data-element=R_VSCtl_aVehPTIni.VSCtl_aVehPTIni
        dr_Ext_stDirMoveVehReq: data-element=R_Ext_stDirMoveVehReq.Ext_stDirMoveVehReq
        dr_VSCtl_bDrvOvrdVSReg_aVeh: data-element=R_VSCtl_bDrvOvrdVSReg_aVeh.VSCtl_bDrvOvrdVSReg_aVeh
        dr_Ext_bASRReg: data-element=R_Ext_bASRReg.Ext_bASRReg
        dr_TqSys_nTarIdl: data-element=R_TqSys_nTarIdl.TqSys_nTarIdl
        dr_Ext_bBrkAutoCf: data-element=R_Ext_bBrkAutoCf.Ext_bBrkAutoCf
        dr_Ext_bCluPedPrss: data-element=R_Ext_bCluPedPrss.Ext_bCluPedPrss
        dr_Ext_stModRegVSCtlReq: data-element=R_Ext_stModRegVSCtlReq.Ext_stModRegVSCtlReq
        dr_Brk_bBrkAuto: data-element=R_Brk_bBrkAuto.Brk_bBrkAuto
        dr_Ext_stDirMoveVeh: data-element=R_Ext_stDirMoveVeh.Ext_stDirMoveVeh
        dr_Ext_bTyreWarn: data-element=R_Ext_bTyreWarn.Ext_bTyreWarn
        dr_VSCtl_bAvlTqWhlPT_no1: data-element=R_VSCtl_bAvlTqWhlPT_no1.VSCtl_bAvlTqWhlPT_no1
        dr_Ext_spdVehVSRegReq: data-element=R_Ext_spdVehVSRegReq.Ext_spdVehVSRegReq
        DRP_R_Ext_bCtlCmdPTTqCf_Ext_bCtlCmdPTTqCf: data-element=R_Ext_bCtlCmdPTTqCf.Ext_bCtlCmdPTTqCf
        dr_SftyMgt_bDeacIrvVSReg: data-element=R_SftyMgt_bDeacIrvVSReg.SftyMgt_bDeacIrvVSReg
        dr_VSCtl_rTqWhlPTDrvReq: data-element=R_VSCtl_rTqWhlPTDrvReq.VSCtl_rTqWhlPTDrvReq
        dr_Veh_spdVeh: data-element=R_Veh_spdVeh.Veh_spdVeh
        dr_Ext_stAcvRegVSCtlReq: data-element=R_Ext_stAcvRegVSCtlReq.Ext_stAcvRegVSCtlReq
        dr_VSCtl_stDeacVSCtlInfo: data-element=R_VSCtl_stDeacVSCtlInfo.VSCtl_stDeacVSCtlInfo
        dr_VSCtl_bEndTranVSReg: data-element=R_VSCtl_bEndTranVSReg.VSCtl_bEndTranVSReg
        dr_AccP_rAccP: data-element=R_AccP_rAccP.AccP_rAccP
        dr_VSCtl_aVehPTMin: data-element=R_VSCtl_aVehPTMin.VSCtl_aVehPTMin
        dr_CoPTSt_stEng: data-element=R_CoPTSt_stEng.CoPTSt_stEng
        dr_Ext_stDVSRegCf: data-element=R_Ext_stDVSRegCf.Ext_stDVSRegCf
        dr_VSCtl_grdRatConvTra: data-element=R_VSCtl_grdRatConvTra.VSCtl_grdRatConvTra
      29 x data send point:
        ds_VSCtl_stCtl_aVehVSReg: data-element=P_VSCtl_stCtl_aVehVSReg.VSCtl_stCtl_aVehVSReg
        ds_VSCtl_stRec_stDeacVSRegReq2: data-element=P_VSCtl_stRec_stDeacVSRegReq2.VSCtl_stRec_stDeacVSRegReq2
        ds_VSCtl_stDeacVSRegReqLo_no2: data-element=P_VSCtl_stDeacVSRegReqLo_no2.VSCtl_stDeacVSRegReqLo_no2
        ds_VSCtl_stVSRegPrev_DeacVSReg: data-element=P_VSCtl_stVSRegPrev_DeacVSReg.VSCtl_stVSRegPrev_DeacVSReg
        ds_VSCtl_aVehPotVSRegReq: data-element=P_VSCtl_aVehPotVSRegReq.VSCtl_aVehPotVSRegReq
        ds_VSCtl_aVeh_DeacVSReg: data-element=P_VSCtl_aVeh_DeacVSReg.VSCtl_aVeh_DeacVSReg
        ds_VSCtl_dstVehTotMes_DeacVSReg: data-element=P_VSCtl_dstVehTotMes_DeacVSReg.VSCtl_dstVehTotMes_DeacVSReg
        ds_VSCtl_tiCfmSupVSRegReq: data-element=P_VSCtl_tiCfmSupVSRegReq.VSCtl_tiCfmSupVSRegReq
        ds_VSCtl_jrkVehReqDeacVSReg: data-element=P_VSCtl_jrkVehReqDeacVSReg.VSCtl_jrkVehReqDeacVSReg
        ds_VSCtl_rCtlTqWhlPTPotVSReg: data-element=P_VSCtl_rCtlTqWhlPTPotVSReg.VSCtl_rCtlTqWhlPTPotVSReg
        ds_VSCtl_spdVehErrVSReg: data-element=P_VSCtl_spdVehErrVSReg.VSCtl_spdVehErrVSReg
        ds_VSCtl_aVehVSRegReq: data-element=P_VSCtl_aVehVSRegReq.VSCtl_aVehVSRegReq
        ds_VSCtl_rSlop_DeacVSReg: data-element=P_VSCtl_rSlop_DeacVSReg.VSCtl_rSlop_DeacVSReg
        ds_VSCtl_stDeacVSRegReqHi_no2: data-element=P_VSCtl_stDeacVSRegReqHi_no2.VSCtl_stDeacVSRegReqHi_no2
        ds_VSCtl_stRec_stDeacVSRegReq1: data-element=P_VSCtl_stRec_stDeacVSRegReq1.VSCtl_stRec_stDeacVSRegReq1
        ds_VSCtl_spdVeh_DeacVSReg: data-element=P_VSCtl_spdVeh_DeacVSReg.VSCtl_spdVeh_DeacVSReg
        ds_VSCtl_posnGBxDeacVSReg: data-element=P_VSCtl_posnGBxDeacVSReg.VSCtl_posnGBxDeacVSReg
        ds_VSCtl_jrkVeh_DeacVSReg: data-element=P_VSCtl_jrkVeh_DeacVSReg.VSCtl_jrkVeh_DeacVSReg
        ds_VSCtl_tiCfmSdwnVSRegReq: data-element=P_VSCtl_tiCfmSdwnVSRegReq.VSCtl_tiCfmSdwnVSRegReq
        ds_VSCtl_bCtl_aVehPotVSReg: data-element=P_VSCtl_bCtl_aVehPotVSReg.VSCtl_bCtl_aVehPotVSReg
        ds_VSCtl_stVSReg_DeacVSReg: data-element=P_VSCtl_stVSReg_DeacVSReg.VSCtl_stVSReg_DeacVSReg
        ds_VSCtl_noGearEgd_DeacVSReg: data-element=P_VSCtl_noGearEgd_DeacVSReg.VSCtl_noGearEgd_DeacVSReg
        ds_VSCtl_stVSRegExtd: data-element=P_VSCtl_stVSRegExtd.VSCtl_stVSRegExtd
        ds_VSCtl_aVehVSRegReq_DeacVSReg: data-element=P_VSCtl_aVehVSRegReq_DeacVSReg.VSCtl_aVehVSRegReq_DeacVSReg
        ds_VSCtl_bDrvOvrdVSReg_spdVeh: data-element=P_VSCtl_bDrvOvrdVSReg_spdVeh.VSCtl_bDrvOvrdVSReg_spdVeh
        ds_VSCtl_stDeacVSRegReqHi_no1: data-element=P_VSCtl_stDeacVSRegReqHi_no1.VSCtl_stDeacVSRegReqHi_no1
        ds_VSCtl_stDeacVSRegReqLo_no1: data-element=P_VSCtl_stDeacVSRegReqLo_no1.VSCtl_stDeacVSRegReqLo_no1
        ds_VSCtl_rAccP_DeacVSReg: data-element=P_VSCtl_rAccP_DeacVSReg.VSCtl_rAccP_DeacVSReg
        ds_VSCtl_spdVehReqDeacVSReg: data-element=P_VSCtl_spdVehReqDeacVSReg.VSCtl_spdVehReqDeacVSReg
      8 x sync call:
        ssp_FRM_bDeacRvVSReg: operation=R_FRM_bDeacRvVSReg.GetFunctionPermission
        ssp_FRM_bInhVSReg: operation=R_FRM_bInhVSReg.GetFunctionPermission
        ssp_FRM_bDeacIrvVSReg: operation=R_FRM_bDeacIrvVSReg.GetFunctionPermission
        ssp_VSCtl_VSReg: operation=R_VSCtl_VSReg.SetEventStatus
        ssp_GetTimer_1ms_U32: operation=R_VSReg_GetTimer_1ms_U32.GetTimer_1ms_U32
        ssp_FRM_bDeacSatMaxSpdVehVSReg: operation=R_FRM_bDeacSatMaxSpdVehVSReg.GetFunctionPermission
        ssp_VSCtl_VSRegVeh: operation=R_VSCtl_VSRegVeh.SetEventStatus
        ssp_VSCtl_VSRegBody: operation=R_VSCtl_VSRegBody.SetEventStatus
  swc implementation Imp_VSReg: programming-language=C, behavior=IB_VSReg
    code-descriptors:
      code CodeDescriptor: type=SRC
        14 x xfile:
          VSREG_Det_Cond_Fct_Brk_Sf_c: url=VSREG_Det_Cond_Fct_Brk_Sf.c
          VSREG_Ctrl_Spd_Veh_Sf_c: url=VSREG_Ctrl_Spd_Veh_Sf.c
          VSREG_Det_Cond_Fct_Gmp_Sf_c: url=VSREG_Det_Cond_Fct_Gmp_Sf.c
          VSREG_Det_Cond_Fct_Veh_Sf_c: url=VSREG_Det_Cond_Fct_Veh_Sf.c
          VSREG_Det_Fct_Diag_Mnt_Sf_c: url=VSREG_Det_Fct_Diag_Mnt_Sf.c
          VSREG_Gmp_Cond_Calc_Sl_c: url=VSREG_Gmp_Cond_Calc_Sl.c
          VSReg_c: url=VSReg.c
          VSREG_Veh_Speed_Control_Sl_c: url=VSREG_Veh_Speed_Control_Sl.c
          VSREG_Brake_Cond_Sl_c: url=VSREG_Brake_Cond_Sl.c
          VSREG_Det_Cond_Fct_Fct_Sf_c: url=VSREG_Det_Cond_Fct_Fct_Sf.c
          VSReg_h: url=VSReg.h
          VSREG_Det_Init_Secu_Fct_Sf_c: url=VSREG_Det_Init_Secu_Fct_Sf.c
          VSREG_Veh_Running_Cond_Sl_c: url=VSREG_Veh_Running_Cond_Sl.c
          VSReg_MemMap_h: url=VSReg_MemMap.h
